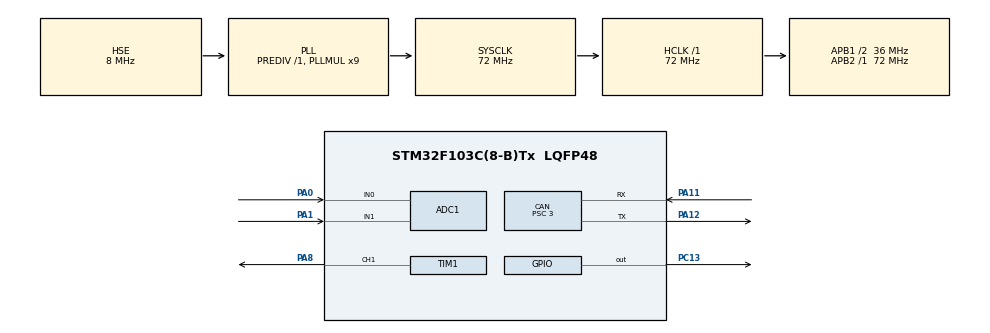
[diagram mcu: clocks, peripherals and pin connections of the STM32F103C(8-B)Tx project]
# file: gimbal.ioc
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ADC1.Channel-0\#ChannelRegularConversion=ADC_CHANNEL_0
ADC1.Channel-1\#ChannelRegularConversion=ADC_CHANNEL_1
ADC1.ContinuousConvMode=ENABLE
ADC1.NbrOfConversion=2
ADC1.NbrOfConversionFlag=1
ADC1.Rank-0\#ChannelRegularConversion=1
ADC1.Rank-1\#ChannelRegularConversion=2
ADC1.SamplingTime-0\#ChannelRegularConversion=ADC_SAMPLETIME_55CYCLES_5
ADC1.SamplingTime-1\#ChannelRegularConversion=ADC_SAMPLETIME_55CYCLES_5
ADC1.master=1
CAN.ABOM=ENABLE
CAN.BS1=CAN_BS1_9TQ
CAN.BS2=CAN_BS2_2TQ
CAN.CalculateBaudRate=999999
CAN.CalculateTimeBit=1000
CAN.CalculateTimeQuantum=83.33333333333334
CAN.Prescaler=3
CAN.SJW=CAN_SJW_1TQ
Dma.ADC1.0.Direction=DMA_PERIPH_TO_MEMORY
Dma.ADC1.0.Instance=DMA1_Channel1
Dma.ADC1.0.MemDataAlignment=DMA_MDATAALIGN_HALFWORD
Dma.ADC1.0.MemInc=DMA_MINC_ENABLE
Dma.ADC1.0.Mode=DMA_CIRCULAR
Dma.ADC1.0.PeriphDataAlignment=DMA_PDATAALIGN_HALFWORD
Dma.ADC1.0.PeriphInc=DMA_PINC_DISABLE
Dma.ADC1.0.Priority=DMA_PRIORITY_LOW
Dma.Request0=ADC1
FREERTOS.Tasks01=input_task,0,128,StartInputTask,Default,NULL,Dynamic,NULL,NULL;can_send_task,-1,128,StartCanSendTask,Default,NULL,Dynamic,NULL,NULL;health_task,-2,128,StartHealthTask,Default,NULL,Dynamic,NULL,NULL;led_task,-2,128,StartLedTask,Default,NULL,Dynamic,NULL,NULL
FREERTOS.configTOTAL_HEAP_SIZE=8192
Mcu.Family=STM32F1
Mcu.Name=STM32F103C(8-B)Tx
Mcu.Package=LQFP48
NVIC.DMA1_Channel1_IRQn=true\:5\:0\:false\:false\:true\:true\:false\:true\:true
NVIC.PriorityGroup=NVIC_PRIORITYGROUP_4
NVIC.TIM4_IRQn=true\:15\:0\:false\:false\:true\:false\:false\:true\:true
NVIC.TimeBase=TIM4_IRQn
NVIC.TimeBaseIP=TIM4
NVIC.USB_LP_CAN1_RX0_IRQn=true\:5\:0\:false\:false\:true\:true\:true\:true\:true
PA0-WKUP.Signal=ADCx_IN0
PA1.Signal=ADCx_IN1
PA11.Mode=CAN_Activate
PA11.Signal=CAN_RX
PA12.Mode=CAN_Activate
PA12.Signal=CAN_TX
PA13.Mode=Serial_Wire
PA13.Signal=SYS_JTMS-SWDIO
PA14.Mode=Serial_Wire
PA14.Signal=SYS_JTCK-SWCLK
PA8.Signal=S_TIM1_CH1
PC13-TAMPER-RTC.Signal=GPIO_Output
PD0-OSC_IN.Mode=HSE-External-Oscillator
PD0-OSC_IN.Signal=RCC_OSC_IN
PD1-OSC_OUT.Mode=HSE-External-Oscillator
PD1-OSC_OUT.Signal=RCC_OSC_OUT
ProjectManager.HeapSize=0x200
ProjectManager.StackSize=0x400
ProjectManager.TargetToolchain=CMake
RCC.ADCPresc=RCC_ADCPCLK2_DIV6
RCC.AHBFreq_Value=72000000
RCC.APB1CLKDivider=RCC_HCLK_DIV2
RCC.APB1Freq_Value=36000000
RCC.APB1TimFreq_Value=72000000
RCC.APB2Freq_Value=72000000
RCC.APB2TimFreq_Value=72000000
RCC.HCLKFreq_Value=72000000
RCC.PLLMUL=RCC_PLL_MUL9
RCC.PLLSourceVirtual=RCC_PLLSOURCE_HSE
RCC.SYSCLKFreq_VALUE=72000000
RCC.SYSCLKSource=RCC_SYSCLKSOURCE_PLLCLK
RCC.USBFreq_Value=72000000
SH.ADCx_IN0.0=ADC1_IN0,IN0
SH.ADCx_IN1.0=ADC1_IN1,IN1
SH.S_TIM1_CH1.0=TIM1_CH1,PWM Generation1 CH1
TIM1.Channel-PWM\ Generation1\ CH1=TIM_CHANNEL_1
TIM1.Period=19999
TIM1.Prescaler=71
TIM1.Pulse-PWM\ Generation1\ CH1=1500
VP_FREERTOS_VS_CMSIS_V1.Mode=CMSIS_V1
VP_SYS_VS_tim4.Mode=TIM4
board=custom

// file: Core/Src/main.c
/* USER CODE BEGIN Header */
/**
  ******************************************************************************
  * @file           : main.c
  * @brief          : Main program body
  ******************************************************************************
  * @attention
  *
  * Copyright (c) 2026 STMicroelectronics.
  * All rights reserved.
  *
  * This software is licensed under terms that can be found in the LICENSE file
  * in the root directory of this software component.
  * If no LICENSE file comes with this software, it is provided AS-IS.
  *
  ******************************************************************************
  */
/* USER CODE END Header */
#include "main.h"
#include "cmsis_os.h"
#include "adc.h"
#include "can.h"
#include "dma.h"
#include "tim.h"
#include "gpio.h"

/* USER CODE BEGIN Includes */
#include "can_bus.h"
#include "adc.h"    // hadc1
/* USER CODE END Includes */

void SystemClock_Config(void);
void MX_FREERTOS_Init(void);

int main(void)
{

  /* MCU Configuration--------------------------------------------------------*/

  /* Reset of all peripherals, Initializes the Flash interface and the Systick. */
  HAL_Init();

  /* Configure the system clock */
  SystemClock_Config();

  /* Initialize all configured peripherals */
  MX_GPIO_Init();
  MX_DMA_Init();
  MX_ADC1_Init();
  MX_CAN_Init();
  MX_TIM1_Init();
  /* USER CODE BEGIN 2 */
  can_bus_init();//can发送函数初始化
  /* USER CODE END 2 */

  /* Call init function for freertos objects (in cmsis_os2.c) */
  MX_FREERTOS_Init();

  /* Start scheduler */
  osKernelStart();

  /* We should never get here as control is now taken by the scheduler */

  /* Infinite loop */
  while (1)
  {

  }
}

void SystemClock_Config(void)
{
  RCC_OscInitTypeDef RCC_OscInitStruct = {0};
  RCC_ClkInitTypeDef RCC_ClkInitStruct = {0};
  RCC_PeriphCLKInitTypeDef PeriphClkInit = {0};

  /** Initializes the RCC Oscillators according to the specified parameters
  * in the RCC_OscInitTypeDef structure.
  */
  RCC_OscInitStruct.OscillatorType = RCC_OSCILLATORTYPE_HSE;
  RCC_OscInitStruct.HSEState = RCC_HSE_ON;
  RCC_OscInitStruct.HSEPredivValue = RCC_HSE_PREDIV_DIV1;
  RCC_OscInitStruct.HSIState = RCC_HSI_ON;
  RCC_OscInitStruct.PLL.PLLState = RCC_PLL_ON;
  RCC_OscInitStruct.PLL.PLLSource = RCC_PLLSOURCE_HSE;
  RCC_OscInitStruct.PLL.PLLMUL = RCC_PLL_MUL9;
  if (HAL_RCC_OscConfig(&RCC_OscInitStruct) != HAL_OK)
  {
    Error_Handler();
  }

  /** Initializes the CPU, AHB and APB buses clocks
  */
  RCC_ClkInitStruct.ClockType = RCC_CLOCKTYPE_HCLK|RCC_CLOCKTYPE_SYSCLK
                              |RCC_CLOCKTYPE_PCLK1|RCC_CLOCKTYPE_PCLK2;
  RCC_ClkInitStruct.SYSCLKSource = RCC_SYSCLKSOURCE_PLLCLK;
  RCC_ClkInitStruct.AHBCLKDivider = RCC_SYSCLK_DIV1;
  RCC_ClkInitStruct.APB1CLKDivider = RCC_HCLK_DIV2;
  RCC_ClkInitStruct.APB2CLKDivider = RCC_HCLK_DIV1;

  if (HAL_RCC_ClockConfig(&RCC_ClkInitStruct, FLASH_LATENCY_2) != HAL_OK)
  {
    Error_Handler();
  }
  PeriphClkInit.PeriphClockSelection = RCC_PERIPHCLK_ADC;
  PeriphClkInit.AdcClockSelection = RCC_ADCPCLK2_DIV6;
  if (HAL_RCCEx_PeriphCLKConfig(&PeriphClkInit) != HAL_OK)
  {
    Error_Handler();
  }
}

void HAL_TIM_PeriodElapsedCallback(TIM_HandleTypeDef *htim)
{
  if (htim->Instance == TIM4)
  {
    HAL_IncTick();
  }
}

void Error_Handler(void)
{
  __disable_irq();
  while (1)
  {
  }
}

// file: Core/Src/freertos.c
/* USER CODE BEGIN Header */
/**
  ******************************************************************************
  * File Name          : freertos.c
  * Description        : Code for freertos applications
  ******************************************************************************
  * @attention
  *
  * Copyright (c) 2026 STMicroelectronics.
  * All rights reserved.
  *
  * This software is licensed under terms that can be found in the LICENSE file
  * in the root directory of this software component.
  * If no LICENSE file comes with this software, it is provided AS-IS.
  *
  ******************************************************************************
  */
/* USER CODE END Header */

#include "FreeRTOS.h"
#include "task.h"
#include "main.h"
#include "cmsis_os.h"

osThreadId input_taskHandle;
osThreadId can_send_taskHandle;
osThreadId health_taskHandle;
osThreadId led_taskHandle;

void StartInputTask(void const * argument);
void StartCanSendTask(void const * argument);
void StartHealthTask(void const * argument);
void StartLedTask(void const * argument);

void MX_FREERTOS_Init(void); /* (MISRA C 2004 rule 8.1) */

/* GetIdleTaskMemory prototype (linked to static allocation support) */
void vApplicationGetIdleTaskMemory( StaticTask_t **ppxIdleTaskTCBBuffer, StackType_t **ppxIdleTaskStackBuffer, uint32_t *pulIdleTaskStackSize );

/* USER CODE BEGIN GET_IDLE_TASK_MEMORY */
static StaticTask_t xIdleTaskTCBBuffer;
static StackType_t xIdleStack[configMINIMAL_STACK_SIZE];

void vApplicationGetIdleTaskMemory( StaticTask_t **ppxIdleTaskTCBBuffer, StackType_t **ppxIdleTaskStackBuffer, uint32_t *pulIdleTaskStackSize )
{
  *ppxIdleTaskTCBBuffer = &xIdleTaskTCBBuffer;
  *ppxIdleTaskStackBuffer = &xIdleStack[0];
  *pulIdleTaskStackSize = configMINIMAL_STACK_SIZE;
  /* place for user code */
}
/* USER CODE END GET_IDLE_TASK_MEMORY */

void MX_FREERTOS_Init(void) {

  /* Create the thread(s) */
  /* definition and creation of input_task */
  osThreadDef(input_task, StartInputTask, osPriorityNormal, 0, 128);
  input_taskHandle = osThreadCreate(osThread(input_task), NULL);

  /* definition and creation of can_send_task */
  osThreadDef(can_send_task, StartCanSendTask, osPriorityBelowNormal, 0, 128);
  can_send_taskHandle = osThreadCreate(osThread(can_send_task), NULL);

  /* definition and creation of health_task */
  osThreadDef(health_task, StartHealthTask, osPriorityLow, 0, 128);
  health_taskHandle = osThreadCreate(osThread(health_task), NULL);

  /* definition and creation of led_task */
  osThreadDef(led_task, StartLedTask, osPriorityLow, 0, 128);
  led_taskHandle = osThreadCreate(osThread(led_task), NULL);

}

__weak void StartInputTask(void const * argument)
{
  /* USER CODE BEGIN StartInputTask */
  /* Infinite loop */
  for(;;)
  {
    osDelay(10);
  }
  /* USER CODE END StartInputTask */
}

__weak void StartCanSendTask(void const * argument)
{
  /* USER CODE BEGIN StartCanSendTask */
  /* Infinite loop */
  for(;;)
  {
    osDelay(5);
  }
  /* USER CODE END StartCanSendTask */
}

__weak void StartHealthTask(void const * argument)
{
  /* USER CODE BEGIN StartHealthTask */
  /* Infinite loop */
  for(;;)
  {
    osDelay(20);
  }
  /* USER CODE END StartHealthTask */
}

__weak void StartLedTask(void const * argument)
{
  for(;;)
  {
    osDelay(1);
  }
}
